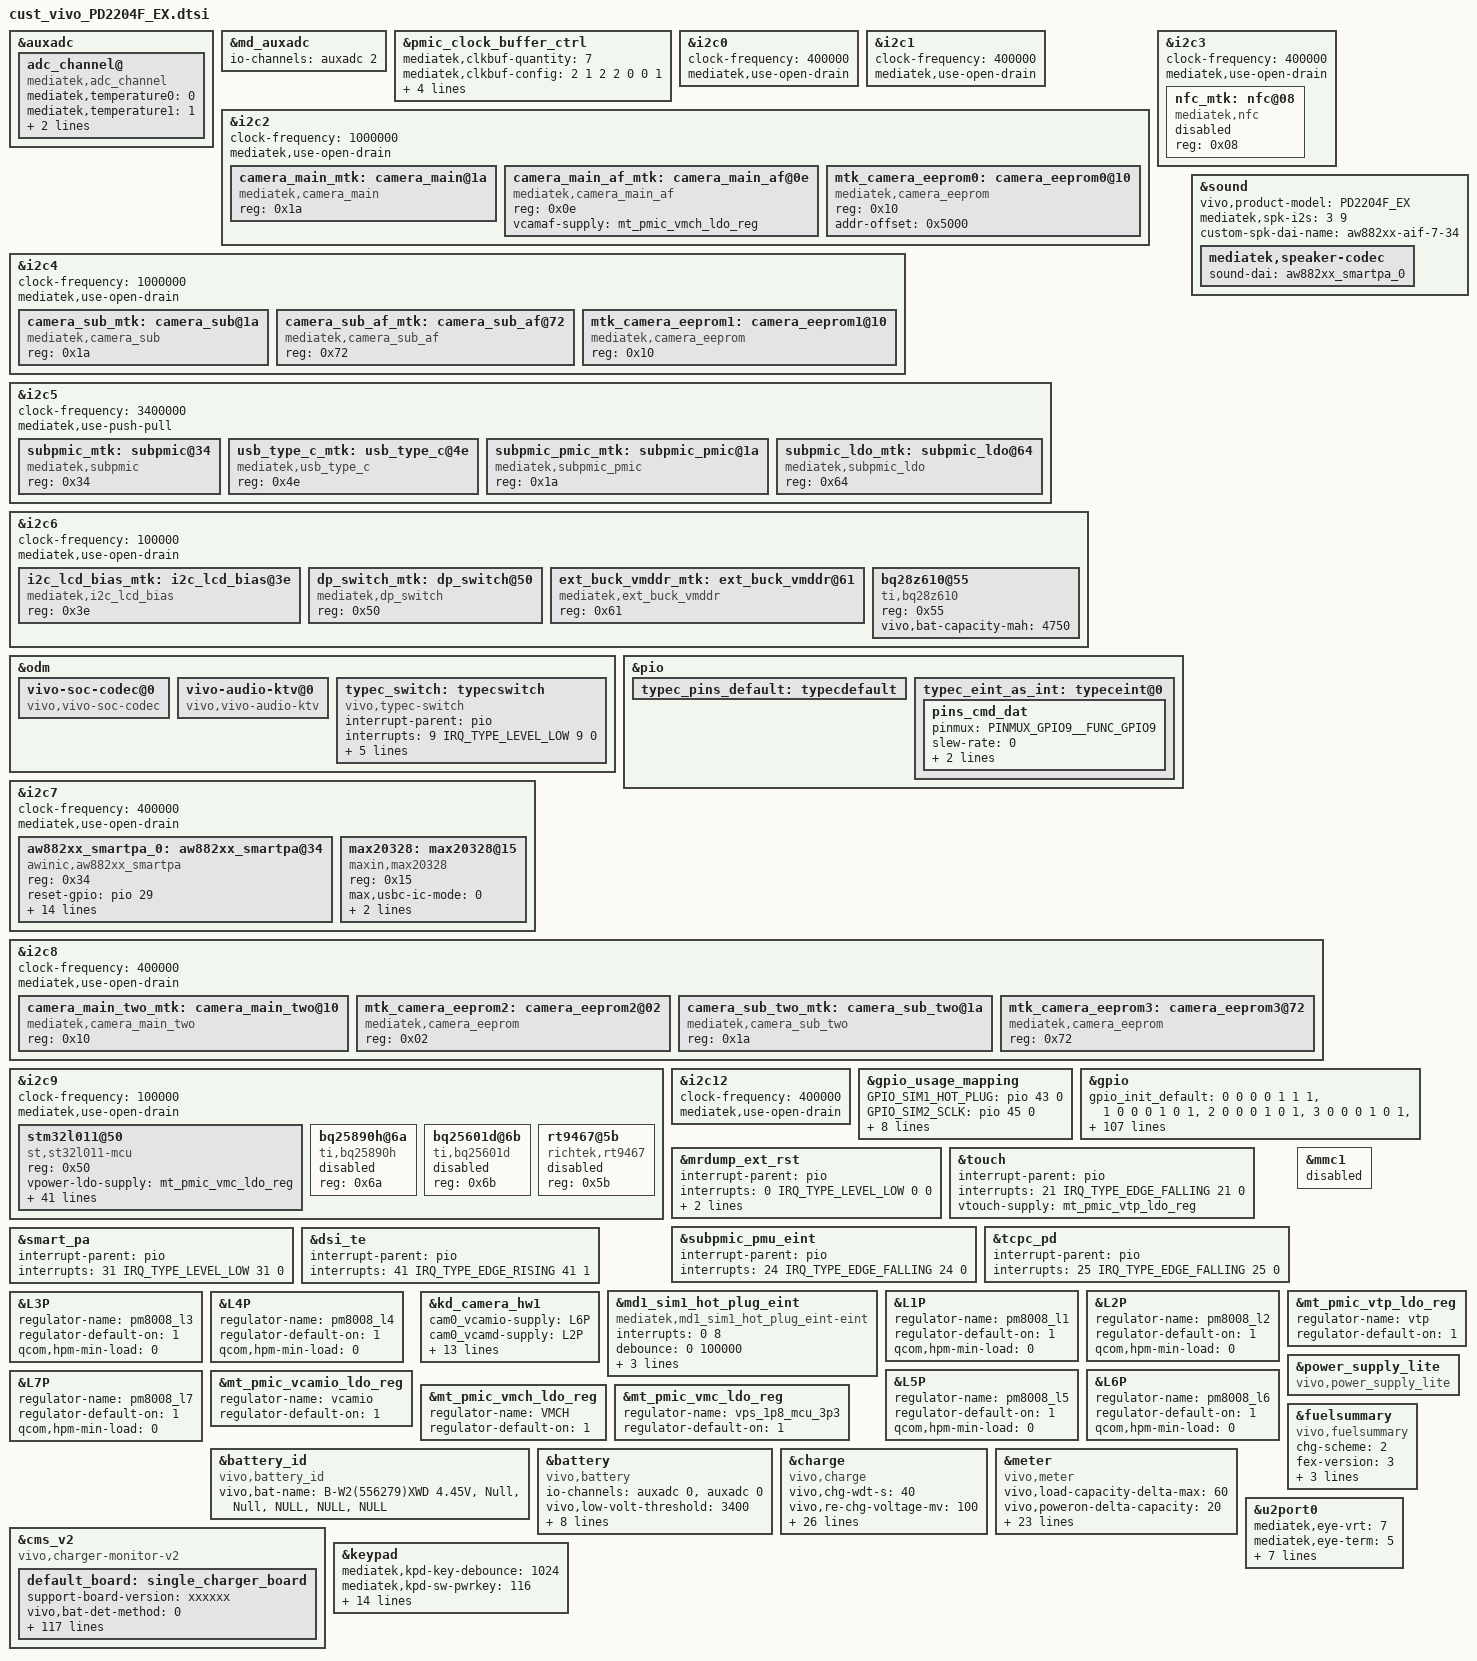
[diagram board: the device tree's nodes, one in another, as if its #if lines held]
/*
 * Generated by MTK SP DrvGen Version: 3.5.160809 for MT6893.
 * 2022-04-22 09:46:38
 * Do Not Modify The File.
 * Copyright Mediatek Inc. (c) 2016.
*/

/*************************
 * ADC DTSI File
*************************/

&auxadc {
	adc_channel@ {
		compatible = "mediatek,adc_channel";
		mediatek,temperature0 = <0>;
		mediatek,temperature1 = <1>;
		mediatek,adc_fdd_rf_params_dynamic_custom_ch = <2>;
		status = "okay";
	};
};
&md_auxadc {
	io-channels = <&auxadc 2>;
};


/*************************
 * CLK_BUF DTSI File
*************************/

&pmic_clock_buffer_ctrl {
	mediatek,clkbuf-quantity = <7>;
	mediatek,clkbuf-config = <2 1 2 2 0 0 1>;
	mediatek,clkbuf-output-impedance = <3 4 3 4 0 0 3>;
	mediatek,clkbuf-controls-for-desense = <0 4 0 4 0 0 0>;
	status = "okay";
};


/*************************
 * I2C DTSI File
*************************/

&i2c0 {
	#address-cells = <1>;
	#size-cells = <0>;
	clock-frequency = <400000>;
	mediatek,use-open-drain;
};

&i2c1 {
	#address-cells = <1>;
	#size-cells = <0>;
	clock-frequency = <400000>;
	mediatek,use-open-drain;
};

&i2c2 {
	#address-cells = <1>;
	#size-cells = <0>;
	clock-frequency = <1000000>;
	mediatek,use-open-drain;
	camera_main_mtk:camera_main@1a {
		compatible = "mediatek,camera_main";
		reg = <0x1a>;
		status = "okay";
	};

	camera_main_af_mtk:camera_main_af@0e {
		compatible = "mediatek,camera_main_af";
		reg = <0x0e>;
		status = "okay";
	};
	mtk_camera_eeprom0:camera_eeprom0@10 {
		compatible = "mediatek,camera_eeprom";
		reg = <0x10>;
		addr-offset = <0x5000>;
		status = "okay";
	};

};

&i2c3 {
	#address-cells = <1>;
	#size-cells = <0>;
	clock-frequency = <400000>;
	mediatek,use-open-drain;
	nfc_mtk:nfc@08 {
		compatible = "mediatek,nfc";
		reg = <0x08>;
		status = "disabled";
	};

};

&i2c4 {
	#address-cells = <1>;
	#size-cells = <0>;
	clock-frequency = <1000000>;
	mediatek,use-open-drain;
	camera_sub_mtk:camera_sub@1a {
		compatible = "mediatek,camera_sub";
		reg = <0x1a>;
		status = "okay";
	};
	camera_sub_af_mtk:camera_sub_af@72 {
		compatible = "mediatek,camera_sub_af";
		reg = <0x72>;
		status = "okay";
	};
	mtk_camera_eeprom1:camera_eeprom1@10 {
		compatible = "mediatek,camera_eeprom";
		reg = <0x10>;
		status = "okay";
	};

};

&i2c5 {
	#address-cells = <1>;
	#size-cells = <0>;
	clock-frequency = <3400000>;
	mediatek,use-push-pull;
	subpmic_mtk:subpmic@34 {
		compatible = "mediatek,subpmic";
		reg = <0x34>;
		status = "okay";
	};

	usb_type_c_mtk:usb_type_c@4e {
		compatible = "mediatek,usb_type_c";
		reg = <0x4e>;
		status = "okay";
	};

	subpmic_pmic_mtk:subpmic_pmic@1a {
		compatible = "mediatek,subpmic_pmic";
		reg = <0x1a>;
		status = "okay";
	};

	subpmic_ldo_mtk:subpmic_ldo@64 {
		compatible = "mediatek,subpmic_ldo";
		reg = <0x64>;
		status = "okay";
	};

};

&i2c6 {
	#address-cells = <1>;
	#size-cells = <0>;
	clock-frequency = <400000>;
	mediatek,use-open-drain;
	i2c_lcd_bias_mtk:i2c_lcd_bias@3e {
		compatible = "mediatek,i2c_lcd_bias";
		reg = <0x3e>;
		status = "okay";
	};

	dp_switch_mtk:dp_switch@50 {
		compatible = "mediatek,dp_switch";
		reg = <0x50>;
		status = "okay";
	};

	ext_buck_vmddr_mtk:ext_buck_vmddr@61 {
		compatible = "mediatek,ext_buck_vmddr";
		reg = <0x61>;
		status = "okay";
	};

};

/* vivo audio dxl add start */
&odm {
	vivo-soc-codec@0 {
		compatible = "vivo,vivo-soc-codec";
		status = "okay";
	};
	vivo-audio-ktv@0 {
		compatible = "vivo,vivo-audio-ktv";
		status = "okay";
	};

	typec_switch:typecswitch {
			compatible = "vivo,typec-switch";
			interrupt-parent = <&pio>;
			interrupts = <9 IRQ_TYPE_LEVEL_LOW 9 0>;
			deb-gpios = <&pio 9 0>;
			debounce = <256000>;
			need_config_Max14743 = <1>;
			pinctrl-names = "default", "typec_eint_as_int";
			pinctrl-0 = <&typec_pins_default>;
			pinctrl-1 = <&typec_eint_as_int>;
			status = "okay";
	};
};

&pio {
	typec_pins_default: typecdefault {
	};
	typec_eint_as_int: typeceint@0 {
			pins_cmd_dat {
					pinmux = <PINMUX_GPIO9__FUNC_GPIO9>;
					slew-rate = <0>;
					/*audio_v: archer modfiy bacause cancel hardware comparator,so not the interrupt.*/
					/*bias-disable;*/
					bias-pull-up;
					input-enable;
			};
	};
};

/* vivo audio dxl add end */

&i2c7 {
	#address-cells = <1>;
	#size-cells = <0>;
	clock-frequency = <400000>;
	mediatek,use-open-drain;
	status = "okay";
	aw882xx_smartpa_0:aw882xx_smartpa@34 {
		compatible = "awinic,aw882xx_smartpa";
		reg = <0x34>;
		#sound-dai-cells = <0>;
		reset-gpio = <&pio 29 0>;
		irq-gpio = <&pio 31 0>;
		sound-channel = <0>;
		//dc-flag = <0>;
		//sync-flag = <0>;
		aw-re-min = <6000>;
		aw-re-max = <10000>;
		aw-cali-mode = "aw_attr";
		aw-cali-check = <1>;

		vivo,Type = "speaker";
		vivo,Impedance-Min-mo = <6000>;
		vivo,Impedance-Max-mo = <10000>;
		vivo,Frequency-Min-hz = <500>;
		vivo,Frequency-Max-hz = <1000>;
		vivo,Qt-Min-1000 = <1000>;
		vivo,VendorID = <63>;       /* AW88263 */
		vivo,aw882xx-acf = "aw882xx_acf_PD2204F_EX.bin";

		status = "okay";
	};
	max20328:max20328@15 {
		status = "okay";
		#sound-dai-cells = <0>;
		compatible = "maxin,max20328";
		reg = <0x15>;
		max,usbc-ic-mode = <0>; /* max20328: 0; fsa4480: 1 */
		jack-type = <1>;   /*0:3.5mm, 1:Type-c*/
		switch-type = <0>; /*0:max20328, 1:FS4480*/
	};
	/* vivo audio dxl add end */
};

&sound {
	vivo,product-model = "PD2204F_EX";
	mediatek,spk-i2s = <3 9>;
	custom-spk-dai-name = "aw882xx-aif-7-34";
	mediatek,speaker-codec {
		sound-dai = <&aw882xx_smartpa_0>;
	};
};

&i2c8 {
	#address-cells = <1>;
	#size-cells = <0>;
	clock-frequency = <400000>;
	mediatek,use-open-drain;
	camera_main_two_mtk:camera_main_two@10 {
		compatible = "mediatek,camera_main_two";
		reg = <0x10>;
		status = "okay";
	};

	mtk_camera_eeprom2:camera_eeprom2@02 {
		compatible = "mediatek,camera_eeprom";
		reg = <0x02>;
		status = "okay";
	};

	camera_sub_two_mtk:camera_sub_two@1a {
		compatible = "mediatek,camera_sub_two";
		reg = <0x1a>;
		status = "okay";
	};
	mtk_camera_eeprom3:camera_eeprom3@72 {
		compatible = "mediatek,camera_eeprom";
		reg = <0x72>;
		status = "okay";
	};
};

&i2c9 {
	#address-cells = <1>;
	#size-cells = <0>;
	clock-frequency = <400000>;
	mediatek,use-open-drain;
	/*
	camera_main_three_mtk:camera_main_three@10 {
		compatible = "mediatek,camera_main_three";
		reg = <0x10>;
		status = "okay";
	};

	camera_main_three_eeprom_mtk:camera_main_three_eeprom@51 {
		compatible = "mediatek,camera_main_three_eeprom";
		reg = <0x51>;
		status = "okay";
	};

	camera_main_three_af_mtk:camera_main_three_af@0c {
		compatible = "mediatek,camera_main_three_af";
		reg = <0x0c>;
		status = "okay";
	};
	*/
};
&i2c12 {
	#address-cells = <1>;
	#size-cells = <0>;
	clock-frequency = <400000>;
	mediatek,use-open-drain;
	#include "pm8008.dtsi"
};


/*************************
 * GPIO DTSI File
*************************/

&gpio_usage_mapping {
	GPIO_SIM1_HOT_PLUG = <&pio 43 0>;
	GPIO_SIM2_SCLK = <&pio 45 0>;
	GPIO_SIM2_SRST = <&pio 46 0>;
	GPIO_SIM2_SIO = <&pio 47 0>;
	GPIO_SIM1_SIO = <&pio 48 0>;
	GPIO_SIM1_SRST = <&pio 49 0>;
	GPIO_SIM1_SCLK = <&pio 50 0>;
	GPIO_FDD_BAND_SUPPORT_DETECT_1ST_PIN = <&pio 70 0>;
	GPIO_FDD_BAND_SUPPORT_DETECT_2ND_PIN = <&pio 185 0>;
};

&gpio{
	gpio_init_default = <0 0 0 0 1 1 1>,
		<1 0 0 0 1 0 1>,
		<2 0 0 0 1 0 1>,
		<3 0 0 0 1 0 1>,
		<4 0 0 0 1 1 1>,
		<5 0 1 0 1 0 1>,
		<6 0 1 0 1 0 1>,
		<7 0 1 0 1 0 1>,
		<8 0 1 0 1 0 1>,
		<9 0 0 0 1 1 1>,
		<10 0 1 0 0 0 0>,//cam3_rst
		<11 0 1 0 0 0 0>,//cam2_rst
		<12 0 0 0 1 1 0>,
		<13 0 1 1 0 0 0>,
		<14 0 1 0 1 0 0>,
		<15 0 0 0 1 0 0>,
		<16 0 0 0 1 0 0>,
		<17 1 0 0 1 0 1>,
		<18 2 0 0 1 0 1>,
		<19 0 1 0 0 0 0>,
		<20 0 0 0 0 1 0>,//pm8008_int
		<21 0 0 0 0 1 1>,
		<22 0 0 0 1 0 1>,
		<23 0 0 0 1 1 1>,
		<24 0 0 0 1 1 1>,
		<25 0 0 0 1 1 1>,
		<26 0 1 0 1 0 1>,
		<27 0 1 1 1 0 1>,
		<28 0 1 0 1 0 1>,
		<29 0 1 0 1 0 1>,
		<30 0 1 0 1 0 1>,
		<31 0 0 0 1 1 1>,
		<32 0 0 0 0 0 1>,
		<33 0 0 0 0 0 1>,
		<34 1 0 0 1 0 1>,
		<35 0 0 0 0 0 1>,
		<36 0 1 0 1 0 0>,
		<37 0 1 0 1 0 0>,
		<38 0 1 0 1 0 0>,
		<39 0 1 0 1 0 0>,
		<40 1 0 0 0 0 0>,
		<41 1 0 0 1 0 0>,
		<42 0 1 0 0 0 0>,
		<43 1 0 0 0 0 1>,
		<44 0 0 0 0 0 0>,
		<45 1 0 0 0 0 1>,
		<46 1 0 0 0 0 1>,
		<47 1 0 0 1 1 1>,
		<48 1 0 0 1 1 1>,
		<49 1 0 0 0 0 1>,
		<50 1 0 0 0 0 1>,
		<51 1 0 0 0 0 1>,
		<52 0 0 0 1 1 1>,
		<53 0 0 0 1 1 1>,
		<54 1 0 0 1 1 1>,
		<55 0 1 0 0 0 1>,
		<56 1 0 0 1 1 1>,
		<57 1 0 0 0 0 0>,
		<58 1 0 0 1 0 0>,
		<59 1 0 0 0 0 0>,
		<60 1 0 0 1 0 0>,
		<61 1 0 0 1 0 0>,
		<62 1 0 0 1 0 1>,
		<63 1 0 0 0 0 1>,
		<64 1 0 0 0 0 1>,
		<65 0 0 0 1 0 0>,
		<66 1 0 0 0 0 1>,
		<67 1 0 0 1 0 0>,
		<68 0 1 1 1 0 0>,
		<69 1 0 0 1 0 0>,
		<70 0 0 0 0 1 1>,
		<71 1 0 0 1 0 0>,
		<72 0 1 1 1 1 0>,
		<73 0 0 0 1 1 0>,
		<74 1 0 0 1 0 0>,
		<75 0 0 0 0 0 1>,
		<76 0 0 0 0 0 1>,
		<77 0 0 0 0 0 1>,
		<78 0 0 0 0 0 1>,
		<79 0 0 0 0 0 1>,
		<80 1 0 0 1 0 0>,
		<81 1 0 0 1 0 0>,
		<82 1 0 0 1 0 0>,
		<83 1 0 0 1 0 0>,
		<84 1 0 0 1 0 0>,
		<85 1 0 0 0 0 0>,
		<86 1 0 0 1 0 0>,
		<87 1 0 0 0 0 0>,
		<88 1 0 0 1 0 0>,
		<89 1 0 0 0 0 1>,
		<90 1 0 0 0 0 1>,
		<92 1 0 0 1 1 0>,
		<93 1 0 0 0 0 0>,
		<94 1 0 0 1 1 0>,
		<95 1 0 0 0 0 0>,
		<96 7 0 0 1 0 0>,
		<97 7 0 0 1 0 0>,
		<98 7 0 0 1 0 0>,
		<99 7 0 0 0 0 0>,
		<100 7 0 0 1 0 0>,
		<101 7 0 0 1 0 0>,
		<102 7 0 0 1 0 0>,
		<103 7 0 0 0 0 0>,
		<104 7 0 0 1 0 0>,
		<105 7 0 0 1 0 0>,
		<106 7 0 0 1 0 0>,
		<107 7 0 0 1 0 1>,
		<108 7 0 0 1 0 0>,
		<109 7 0 0 1 0 0>,
		<110 0 1 0 1 0 0>,
		<111 0 1 0 1 0 0>,
		<112 0 1 0 1 0 0>,
		<113 0 1 0 1 0 0>,
		<114 2 0 0 1 0 0>,
		<115 2 1 0 0 0 0>,
		<116 2 1 0 0 0 0>,
		<117 2 1 0 0 0 0>,
		<118 2 0 0 1 1 1>,
		<119 2 0 0 1 1 1>,
		<120 1 0 0 1 1 1>,
		<121 1 0 0 1 1 1>,
		<122 1 0 0 0 0 1>,//i2c-8  scl  cam2_cam3
		<123 1 0 0 0 0 1>,//i2c-8  sda  cam2_cam3
		<124 1 0 0 1 1 1>,
		<125 1 0 0 1 1 1>,
		<126 4 0 0 1 0 0>,
		<127 4 0 0 1 0 0>,
		<128 5 0 0 0 0 1>,//pm8008_scl
		<129 5 0 0 0 0 1>,//pm8008_sda
		<130 1 0 0 1 0 0>,
		<131 0 1 0 0 0 0>,//cam1_rst
		<132 0 1 0 0 0 0>,//cam0_rst
		<133 0 1 1 1 1 1>,//pm8008_rst
		<134 0 1 1 1 1 1>,//pm8008_en
		<135 0 1 0 0 0 0>,//cam2_dvdd
		<136 0 1 0 1 0 0>,//usb_sw_sel
		<137 1 1 0 0 0 0>,//cam1_mclk
		<138 0 0 0 0 0 0>,
		<139 1 0 0 0 0 1>,//i2c-4  scl  cam1
		<140 1 0 0 0 0 1>,//i2c-4  sda  cam1
		<141 1 0 0 0 0 1>,//i2c-2  scl  cam0
		<142 1 0 0 0 0 1>,//i2c-2  sda  cam0
		<143 0 1 0 1 0 0>,
		<144 0 1 0 1 0 0>,
		<145 0 1 0 1 0 0>,
		<146 0 1 0 1 0 0>,
		<147 0 1 0 1 0 0>,
		<148 0 1 0 1 0 0>,
		<149 1 1 0 0 0 0>,//cam0_mclk
		<150 1 1 0 0 0 0>,//cam3_mclk
		<151 1 1 0 0 0 0>,//cam2_mclk
		<152 0 0 0 1 0 0>,
		<153 1 0 0 0 0 0>,
		<154 1 0 0 1 1 0>,
		<155 0 0 0 0 0 0>,
		<156 1 0 0 0 0 0>,
		<157 1 0 0 0 0 0>,
		<158 1 0 0 0 0 0>,
		<159 1 0 0 0 0 0>,
		<160 1 0 0 1 1 1>,
		<161 1 0 0 1 1 1>,
		<162 0 0 0 1 0 1>,
		<163 0 0 0 1 0 1>,
		<164 0 0 0 1 0 1>,
		<165 1 0 0 1 0 1>,
		<166 1 0 0 1 0 1>,
		<167 0 0 0 1 0 1>,
		<168 6 0 0 1 1 1>,
		<169 6 0 0 1 1 1>,
		<170 6 0 0 1 1 1>,
		<171 6 0 0 1 1 1>,
		<172 0 0 0 1 0 0>,
		<173 0 0 0 1 0 0>,
		<174 0 0 0 1 0 0>,
		<175 0 0 0 1 0 0>,
		<176 0 0 0 1 0 0>,
		<177 0 0 0 1 0 0>,
		<178 0 0 0 1 0 0>,
		<179 0 0 0 1 0 0>,
		<180 0 0 0 1 0 0>,
		<181 0 0 0 1 0 0>,
		<182 0 0 0 1 0 0>,
		<183 0 1 0 1 1 0>,
		<184 0 0 0 0 0 1>,
		<185 0 0 0 0 1 1>,
		<190 0 1 1 0 0 0>,
		<194 0 1 0 0 0 0>,
		<195 1 0 0 0 0 0>,
		<196 1 0 0 0 0 1>,
		<197 1 0 0 0 0 1>,
		<198 1 0 0 0 0 1>,
		<199 1 0 0 1 0 1>,
		<200 1 0 1 1 1 1>,
		<201 1 0 1 1 1 1>,
		<202 1 0 0 1 1 1>,
		<203 1 0 0 1 1 1>,
		<204 1 0 0 0 1 1>,
		<205 1 0 0 0 1 1>,
		<206 1 0 0 0 0 0>,
		<207 1 0 0 0 0 0>,
		<208 1 0 0 0 0 0>,
		<209 1 0 0 1 0 0>,
		<210 1 0 0 0 0 0>,
		<211 1 0 0 0 0 0>,
		<212 1 0 0 0 0 0>,
		<213 1 0 0 1 0 0>,
		<214 1 0 0 0 0 1>,
		<215 1 0 0 0 0 1>,
		<216 1 0 0 0 0 1>,
		<217 1 0 0 0 0 1>,
		<218 1 0 0 1 0 1>,
		<219 1 0 0 1 0 1>,
		<220 0 0 0 1 0 0>,
		<221 0 0 0 1 0 0>,
		<222 0 0 0 1 0 0>,
		<223 0 0 0 1 0 0>,
		<224 0 0 0 1 0 0>,
		<225 0 0 0 1 0 0>,
		<226 0 0 0 1 0 0>;
};


/*************************
 * EINT DTSI File
*************************/

#include <dt-bindings/interrupt-controller/irq.h>
#include <dt-bindings/interrupt-controller/arm-gic.h>

&mrdump_ext_rst {
	interrupt-parent = <&pio>;
	interrupts = <0 IRQ_TYPE_LEVEL_LOW 0 0>;
	deb-gpios = <&pio 0 0>;
	debounce = <512000>;
	status = "okay";
};

&touch {
	interrupt-parent = <&pio>;
	interrupts = <21 IRQ_TYPE_EDGE_FALLING 21 0>;
	status = "okay";
};

&subpmic_pmu_eint {
	interrupt-parent = <&pio>;
	interrupts = <24 IRQ_TYPE_EDGE_FALLING 24 0>;
	status = "okay";
};

&tcpc_pd {
	interrupt-parent = <&pio>;
	interrupts = <25 IRQ_TYPE_EDGE_FALLING 25 0>;
	status = "okay";
};

&smart_pa {
	interrupt-parent = <&pio>;
	interrupts = <31 IRQ_TYPE_LEVEL_LOW 31 0>;
	status = "okay";
};

&dsi_te {
	interrupt-parent = <&pio>;
	interrupts = <41 IRQ_TYPE_EDGE_RISING 41 1>;
	status = "okay";
};



/*************************
 * MD1_EINT DTSI File
*************************/

&md1_sim1_hot_plug_eint {
	compatible = "mediatek,md1_sim1_hot_plug_eint-eint";
	interrupts = <0 8>;
	debounce = <0 100000>;
	dedicated = <0 0>;
	src_pin = <0 1>;
	sockettype = <0 0>;
	status = "okay";
};



/*************************
 * PMIC DTSI File
*************************/
/* hope add pm8008 pmic start*/
&L1P {
	regulator-name = "pm8008_l1";
	regulator-default-on = <1>; /* 0:skip, 1: off, 2:on */
	qcom,hpm-min-load = <0>;
	status = "okay";
};
&L2P {
	regulator-name = "pm8008_l2";
	regulator-default-on = <1>; /* 0:skip, 1: off, 2:on */
	qcom,hpm-min-load = <0>;
	status = "okay";
};
&L3P {
	regulator-name = "pm8008_l3";
	regulator-default-on = <1>; /* 0:skip, 1: off, 2:on */
	qcom,hpm-min-load = <0>;
	status = "okay";
};
&L4P {
	regulator-name = "pm8008_l4";
	regulator-default-on = <1>; /* 0:skip, 1: off, 2:on */
	qcom,hpm-min-load = <0>;
	status = "okay";
};
&L5P {
	regulator-name = "pm8008_l5";
	regulator-default-on = <1>; /* 0:skip, 1: off, 2:on */
	qcom,hpm-min-load = <0>;
	status = "okay";
};
&L6P {
	regulator-name = "pm8008_l6";
	regulator-default-on = <1>; /* 0:skip, 1: off, 2:on */
	qcom,hpm-min-load = <0>;
	status = "okay";
};
&L7P {
	regulator-name = "pm8008_l7";
	regulator-default-on = <1>; /* 0:skip, 1: off, 2:on */
	qcom,hpm-min-load = <0>;
	status = "okay";
};
/* hope add pm8008 pmic end*/

&mmc1 {
    status = "disabled";//disable vmc_ldo
};

&mt_pmic_vcamio_ldo_reg {
	regulator-name = "vcamio";
	regulator-default-on = <1>; /* 0:skip, 1: off, 2:on */
	status = "okay";
};
&mt_pmic_vtp_ldo_reg {
	regulator-name = "vtp";
	regulator-default-on = <1>; /* 0:skip, 1: off, 2:on */
	status = "okay";
};

&kd_camera_hw1 {
	cam0_vcamio-supply = <&L6P>;
	cam0_vcamd-supply = <&L2P>;
	cam0_vcama-supply = <&L3P>;
	cam0_vcamoisa-supply = <&L7P>;

	cam1_vcamio-supply = <&L6P>;
	cam1_vcamd-supply = <&L1P>;
	cam1_vcama-supply = <&L4P>;

	cam2_vcamio-supply = <&L6P>;

	cam2_vcama-supply = <&L5P>;
	cam3_vcamio-supply = <&L6P>;
	cam3_vcama-supply = <&L5P>;
	cam0_enable_sensor = "s5kgw1sd03pd2204f_mipi_raw";
	cam1_enable_sensor = "s5kgd2smpd2204f_mipi_raw";
	cam2_enable_sensor = "ov8856pd2204f_mipi_raw";
	cam3_enable_sensor = "ov02b10pd2204f_mipi_raw";
	status = "okay";
};
&camera_main_af_mtk {
	vcamaf-supply = <&mt_pmic_vmch_ldo_reg>;
};

&touch {
	vtouch-supply = <&mt_pmic_vtp_ldo_reg>;
	status = "okay";
};
&mt_pmic_vmch_ldo_reg {
	regulator-name = "VMCH";
	regulator-default-on = <1>; /* 0:skip, 1: off, 2:on */
	status = "okay";
};

/*************************
 * POWER DTSI File
*************************/
&mt_pmic_vmc_ldo_reg {
	regulator-name = "vps_1p8_mcu_3p3";
	regulator-default-on = <1>; /* 0:skip, 1: off, 2:on */
	status = "okay";
};


/* fuxi add for battery&charge start */
#ifdef CONFIG_VIVO_CHARGING_NEW_ARCH
&battery_id {
	status = "okay";
	compatible = "vivo,battery_id";

	//vivo,bat-adc-ctrl-gpio = <&pio 28 0>;

	//io-channels = <&auxadc 5>;
	//io-channel-names = "battery_id_adc";

	vivo,bat-name = "B-W2(556279)XWD 4.45V","Null","Null","NULL","NULL","NULL";
};

&battery {
	status = "okay";
	compatible = "vivo,battery";

	io-channels = <&auxadc 0>,
		<&auxadc 0>;
	io-channel-names = "primary_board_therm",
		"parallel_board_therm";

	vivo,low-volt-threshold = <3400>;
	vivo,soft-rise-percent = <98>;
	vivo,soft-rise-cumulative = <2>;
	vivo,soft-rise-keep-cumulative = <8>;
	vivo,percnet-sync-delta = <1>;
	vivo,percnet-sync-cumulative = <9>;
	vivo,full-sync-cumulative = <1>;
	vivo,soft-term-percent = <99>;
	vivo,soft-term-cumulative = <15>;
};

&charge {
	status = "okay";
	compatible = "vivo,charge";

	vivo,chg-wdt-s = <40>;
	vivo,re-chg-voltage-mv = <100>;
	vivo,prechg-voltage-mv = <3000>;
	vivo,iprechg-current-ma = <300>;
	vivo,iterm-current-ma = <300>;
	vivo,vreg-voltage-mv = <4460>;
	vivo,vindpm-voltage-mv = <4600>;
	vivo,sys-voltage-min-mv= <3500>;
	vivo,boostv-voltage-mv = <5150>;
	vivo,boostv-ilimit-ma = <1500>;
	vivo,ovp-voltage-mv = <15000>;

	/*
	 * 0  auto detect charging
	 * 1  vivo-normal chargine
	 * 2  vivo-single engine charging
	 * 3  vivo-dual engine charging
	 * 4  vivo-flash charging
	 */
	vivo,charge-scheme = <0>;
	vivo,direct-charger-enable;

	/*
	 * SUPPORTED_ADAPTER_DEFAULT = 0,
	 * SUPPORTED_ADAPTER_VIVO_LV_DCHG_5V_4500MA = 1,
	 * SUPPORTED_ADAPTER_VIVO_HV_DCHG_10V_2250MA = 2,
	 * SUPPORTED_ADAPTER_QC20__9V_2000MA = 3,
	 * SUPPORTED_ADAPTER_VIVO_HV_DCHG_10V_4000MA = 4,
	 * SUPPORTED_ADAPTER_MAX,
	 */
	vivo,supported-adapter = <4>;

	//parameter for 9V2A
	vivo,primary-ichg-max-ma = <2600>;
	vivo,parallel-ichg-max-ma = <1680>;

	vivo,flashchg-spec-ma = <2000 3300 12000>;
	vivo,fastchg-spec-ma = <2000 2100 3800>;
	vivo,normalchg-spec-ma = <2000 1500 2300>;

	/* 0---PMIC; 1---CHGIC */
	vivo,vbus-detect-source = <1>;

	//vivo,usboe-gpio = <&pio 13 0>;

	/*ffc*/
	//vivo,ffc-enable;
	vivo,ffc-iterm-ma = <(-750)>;
	vivo,ffc-vreg-mv = <4490>;
	vivo,ffc-temperature-range = <150 450>;
	vivo,ffc-full-vbat-table-size = <3>;
	vivo,ffc-full-vbat-table = <4470 4470 4430>;
	vivo,ffc-full-ibat-table-size = <3>;
	vivo,ffc-full-ibat-table =<150 199 (-903)>,
		<200 349 (-1164)>,
		<350 449 (-1259)>;
};

&meter {
	status = "okay";
	compatible = "vivo,meter";

	vivo,load-capacity-delta-max = <60>;
	vivo,poweron-delta-capacity = <20>;
	vivo,poweron-low-capacity = <3>;
	vivo,volt-car-delta = <8>;
	vivo,car-volt-delta = <6>;
	vivo,meter-res-compesate = <0>;
	vivo,ocv-board-compesate = <0>;
    	vivo,shipmode-cap-limit = <40>;
	vivo,shipmode-vol-limit = <4000>;

	/* 0---AGING_UNSUPPORTED; 1---DRIVER_SUPPORTED; 2---USPACE_SUPPORTED */
	vivo,battery-aging-support = <2>;

	vivo,capacity-mAh = <4750>;
	/*COLD_CHG COLD_DISCHG NORMAL_CHG NORMAL_DISCHG*/
	vivo,car-tune-value = <1000 1000 1000 1000>,
		<1000 1000 1000 1000>,
		<1000 1000 1000 1000>,
		<1000 1000 1000 1000>,
		<1000 1000 1000 1000>,
		<1000 1000 1000 1000>;
	vivo,bats-qmax = <4100 4200 4320 4480 4480>,
		<3492 3675 3933 4005 4097>,
		<3492 3675 3933 4005 4097>,
		<3492 3675 3933 4005 4097>,
		<3492 3675 3933 4005 4097>,
		<3492 3675 3933 4005 4097>;

	/* car-tune adjust remap */
	vivo,car-tune-adjust-enable;
	vivo,car-tune-adjust-size = <3>;
	vivo,car-tune-adjust-table = <0 10 (330) 7>,
		<11 20 (-30) 9>,
		<21 100 (-30) 11>;

	#include "bat_setting/PD2204F_EX_battery_table.dtsi"
};

&cms_v2 {
	compatible = "vivo,charger-monitor-v2";
	status = "okay";

	default_board: single_charger_board {
		       /*default board: keep in xxxxxx*/
		       support-board-version = "xxxxxx";

		       vivo,bat-det-method = <0>;//r:0, rc:1, eprom:2, ex-fg:3
		       vivo,bat-id-gpio = <&pio 28 0>;

		       /*
			  CHG0__CHARGING_TECHNOLOGY_NONE = 0,
			  CHG1__NORMAL_CHARGING,			//5V/2A normal charging
			  CHG2__QC2_CHARGING,				//9V/2A	QC2.0 charging
			  CHG3__LOW_VOLTAGE_DIRECT_CHARGING,		//5V/4.5A direct charging
			  CHG4__SINGLE_IC_DIV2_CHARGING,		//single IC Div/2 charging
			  CHG5__DUAL_IC_DIV2_CHARGING,			//Dual IC Div/2 charging
			  CHG6__DUAL_IC_DUAL_BATTERY_DIV2_CHARGING,	//Dual IC Div/2 charging
			  CHGX__CHARGING_TECHNOLOGY_MAX,
			*/
		       vivo,charging-technology = <5>;

		       //vivo,no-bat-warning;
		       //vivo,no-chg-timeout;
		       vivo,chg-timeout-mins = <900>;

		       //high temperature charger current control enable
		       vivo,htccc-enable;
		       vivo,htccc-data = <46 55 4000000 100000>;

		       //vivo,fbon-scale-enable;/*disable default*/
		       vivo,fbon-scale-data = <2 100 100>;

		       //vivo,switch-scale-enable;/*disable from rom4.0*/
		       vivo,switch-scale-data = <75 53>;

		       vivo,calling-scale-enable;
		       vivo,calling-scale-data = <100 21>;/*ibat:3900 * 0.54 = 2106,more than 1500,not exit dchg*/
		       vivo,calling-dchg-disable;

		       vivo,weixin-calling-scale-enable;
		       vivo,weixin-calling-scale-data = <100 106>;/*5000mA*/

		       vivo,carlife-scale-enable;
		       vivo,carlife-scale-data = <100 12>;/*500mA*/

		       //vivo,fixed-scale-enable;
		       vivo,fixed-scale-data = <120 3800 0>;/*dchg fixed time adjust the max ibat,disable default*/

		       /*data processing : batt-temp*/
		       vivo,dp-batt-temp-enable;
		       vivo,dp-batt-temp-data = <100>;

		       vivo,vbat-r-comp = <0>;

		       /* charging current for devices in exhibition mode */
		       vivo,exhibition-mode-current-primary = <2048>;
		       vivo,exhibition-mode-current-parallel = <0>;

		       /*default tc parameter*/
		       //single charger ibat scale base on temperature battery cell info:1C/1.2C 3960mah
		       /* tmin, tmax, data, volt1, data_ex1, volt2, data_ex2. */
		       vivo,normal-tc-row-col = <8 9>;
		       vivo,normal-tc-data = <541 8888 0 0 0 0 0 0 0>,
			       <450 540 60 0 0 0 0 0 0>,
			       <200 449 253 4200000 211 4250000 168 0 0>,
			       <150 199 168 4250000 126 0 0 0 0>,
			       <100 149 150 4250000 120 0 0 0 0>,
			       <50 99 100 0 0 0 0 0 0>,
			       <0 49 100 0 0 0 0 0 0>,
			       <(-8888) (-1) 0 0 0 0 0 0 0>;

		       /*flash tc parameter*/
		       vivo,flash-normal-tc-row-col = <10 9>;
		       vivo,flash-normal-tc-data = <541 8888 0 0 0 0 0 0 0>,
			       <450 540 60 0 0 0 0 0 0>,
			       <350 449 253 4220000 210 4250000 160 4430000 140>,
			       <200 349 253 4220000 210 4250000 160 4430000 140>,
			       <150 199 168 4250000 126 4350000 120 4430000 80>,
			       <100 149 150 4250000 120 0 0 0 0>,
			       <50 99 100 0 0 0 0 0 0>,
			       <0 49 100 0 0 0 0 0 0>,
			       <(-50) (-1) 0 0 0 0 0 0 0>,
			       <(-8888) (-51) 0 0 0 0 0 0 0>;

		       /*adjust fastchg base on board temperature and fb off*/
		       vivo,intell-charge-enable;
		       vivo,parallel-temp-enable = <0 0>;//<x y> x:fb-on y:fb-off

		       /* Flash charge fb-on intell param */
		       vivo,primary-fbon-tc-row-col = <9 3>;
		       vivo,primary-fbon-tc-data = <481 8888 1600>,
			       <461 480 2100>,
			       <451 460 2600>,
			       <441 450 3800>,
			       <426 440 4900>,
			       <406 425 6000>,
			       <376 405 7500>,
			       <331 375 10000>,
			       <(-8888) 330 12000>;

		       vivo,parallel-fbon-tc-row-col = <2 3>;
		       vivo,parallel-fbon-tc-data = <481 8888 1600>,
			       <(-8888) 480 12000>;

		       /* Flash charge fb-off intell param */
		       vivo,primary-fboff-tc-row-col = <9 3>;
		       vivo,primary-fboff-tc-data = <461 8888 1600>,
			       <441 460 2500>,
			       <426 440 3200>,
			       <411 425 4100>,
			       <396 410 5400>,
			       <371 395 5900>,
			       <361 370 7700>,
			       <331 360 10000>,
			       <(-8888) 330 12000>;

		       vivo,parallel-fboff-tc-row-col = <2 3>;
		       vivo,parallel-fboff-tc-data = <461 8888 1600>,
			       <(-8888) 460 12000>;


		       /* 9v Fast charge fb-on intell param */
		       vivo,9v-primary-fbon-tc-row-col = <7 3>;
		       vivo,9v-primary-fbon-tc-data = <481 8888 500>,
			       <461 480 700>,
			       <441 460 900>,
			       <421 440 1300>,
			       <401 420 1700>,
			       <381 400 2100>,
			       <(-8888) 380 2500>;
		       vivo,9v-parallel-fbon-tc-row-col = <7 3>;
		       vivo,9v-parallel-fbon-tc-data = <481 8888 500>,
			       <461 480 800>,
			       <441 460 900>,
			       <421 440 1300>,
			       <401 420 1700>,
			       <381 400 2100>,
			       <(-8888) 380 2500>;
		       // second parallel parameter, for rt9467
		       vivo,9v-2nd-parallel-fbon-tc-row-col = <3 3>;
		       vivo,9v-2nd-parallel-fbon-tc-data = <401 8888 512>,
			       <386 400 800>,
			       <(-8888) 385 1000>;


		       /* 9v Fast charge fb-off intell param */
		       vivo,9v-primary-fboff-tc-row-col = <7 3>;
		       vivo,9v-primary-fboff-tc-data = <451 8888 800>,
			       <441 450 1100>,
			       <431 440 1300>,
			       <421 430 1600>,
			       <411 420 1900>,
			       <401 410 2200>,
			       <(-8888) 400 2500>;
		       vivo,9v-parallel-fboff-tc-row-col = <7 3>;
		       vivo,9v-parallel-fboff-tc-data = <451 8888 800>,
			       <441 450 1100>,
			       <431 440 1300>,
			       <421 430 1600>,
			       <411 420 1900>,
			       <401 410 2200>,
			       <(-8888) 400 2500>;
		       // second parallel parameter, for rt9467
		       vivo,9v-2nd-parallel-fboff-tc-row-col = <6 3>;
		       vivo,9v-2nd-parallel-fboff-tc-data = <431 8888 500>,
			       <411 430 700>,
			       <381 410 790>,
			       <371 380 1050>,
			       <351 370 1300>,
			       <(-8888) 350 1500>;


		       /* 5v Normal charge fb-on intell param */
		       vivo,5v-primary-fbon-tc-row-col = <6 3>;
		       vivo,5v-primary-fbon-tc-data = <481 8888 500>,
			       <461 480 700>,
			       <441 460 900>,
			       <421 440 1300>,
			       <401 420 1700>,
			       <(-8888) 400 2000>;

		       vivo,5v-parallel-fbon-tc-row-col = <1 3>;
		       vivo,5v-parallel-fbon-tc-data = <(-8888) 8888 0>;

		       /* 5v Normal charge fb-off intell param */
		       vivo,5v-primary-fboff-tc-row-col = <6 3>;
		       vivo,5v-primary-fboff-tc-data = <451 8888 800>,
			       <441 450 1100>,
			       <431 440 1300>,
			       <421 430 1600>,
			       <411 420 1900>,
			       <(-8888) 410 2000>;

		       vivo,5v-parallel-fboff-tc-row-col = <1 3>;
		       vivo,5v-parallel-fboff-tc-data = <(-8888) 8888 0>;

		       // Direct charging param
		       vivo,direct-charger-enable;//porting_check
		       vivo,ex-bms-psy-name = "bq_bms";

		       // bat_baord, usb_conn, pcb_conn(master_bat_conn), bat_conn
		       vivo,dchg-ntc-protect-enable;
		       vivo,dchg-ntc-protect-data = <750 800 850 850>;

		       vivo,adapter-cooldown-data = <900 850 3400>;
		       /*adapter power derate*/
		       vivo,adapter-power-derate-enable;

		       /* usb connecter protect param
			* USB_PROTECT_NONE = 0,
			* USB_CONN_TEMP_HEAT_PROTECT = BIT(0),
			* USB_ID_PROTECT = BIT(1),
			*/
		       vivo,usb-connecter-protect-enable = <1>;
		       vivo,usb-id-protect-data= <1100 1547 500>;/* 500K, 2M, fcc */
		       vivo,usb-conn-heat-protect-data-row-col = <2 4>;
		       vivo,usb-conn-heat-protect-data= <260 8888 670 620>,
			       <(-8888) 259 570 520>;

		       /*
			* max vbus of adapter:11v, max ibus of adapter:5A
			* min voltage of battery for half chg:3500mV,max voltage of battery for half charge:4100mV,
			* 5V2A charge min current threshold: 1000mA,5V2A charge max current threshold:2100mA,
			* flash charge min current threshold:5000mA,flash charge max current threshold:11000mA
			*/

		       /*default parameter*/
		       vivo,charge-param-judge-threshold = <5 2 3500 4300 1000 2100 5000 11000>;
		       /* factory mode charging test param */
		       vivo,charge-test-param-row-col = <12 3>;
		       vivo,charge-test-param-data = <0 0 5500>, /* cable resistance, min value, max value */
			       <0 0 5500>, /* master ibus, min ibus, max ibus */
			       <0 0 5500>, /* slave ibus, min ibus, max ibus */
			       <1 20 40>, /* batt therm ntc, min value, max value */
			       <1 20 45>, /* board therm ntc, min value, max value */
			       <0 20 50>, /* sub charger ntc, min value, max value */
			       <0 20 45>, /* usb con ntc, min value, max value */
			       <0 20 45>, /* usb con 1 ntc, double usb NTC, min value, max value */
			       <0 20 45>, /* bat btb master ntc, min value, max value */
			       <0 20 50>, /* bat btb sub ntc, min value, max value */
			       <0 20 50>, /* bat board ntc, min value, max value */
			       <0 20 50>; /* wireless charge coil ntc, min value, max value */

		       /*flash parameter*/
		       vivo,flash-charge-param-judge-threshold = <11 6 3500 4100 1000 2200 8000 12000>;
		       /* factory mode charging test param */
		       vivo,flash-charge-test-param-row-col = <12 3>;
		       vivo,flash-charge-test-param-data = <1 0 5500>, /* cable resistance, min value, max value */
			       <1 0 5500>, /* master ibus, min ibus, max ibus */
			       <1 0 5500>, /* slave ibus, min ibus, max ibus */
			       <1 20 40>, /* batt therm ntc, min value, max value */
			       <1 20 45>, /* board therm ntc, min value, max value */
			       <0 20 50>, /* sub charger ntc, min value, max value */
			       <1 20 45>, /* usb con ntc, min value, max value */
			       <0 20 45>, /* usb con 1 ntc, double usb NTC, min value, max value */
			       <1 20 45>, /* bat btb master ntc, min value, max value */
			       <0 20 50>, /* bat btb sub ntc, min value, max value */
			       <0 20 50>, /* bat board ntc, min value, max value */
			       <0 20 50>; /* wireless charge coil ntc, min value, max value */

		       #include "bat_setting/PD2204F_EX_battery_chg_params.dtsi"
	       };
};

&power_supply_lite {
	status = "okay";
	compatible = "vivo,power_supply_lite";
};

&fuelsummary {
	status = "okay";
	compatible = "vivo,fuelsummary";

	/************************************************************
	 *
	 *  0   vivo-fastchg
	 *  1   qcom-dualchg
	 *  2   mtk-dualchg
	 *  3   qcom-normchg
	 *  4   mtk-normchg
	 *
	 ***********************************************************/
	chg-scheme = <2>;
	fex-version = <3>;
	fbon-ibat = <(-900)>;
	fboff-ibat = <(-1000)>;

	/* 0---AGING_UNSUPPORTED; 1---DRIVER_SUPPORTED; 2---USPACE_SUPPORTED */
	vivo,battery-aging-support = <2>;
};

&i2c6 {
	status = "okay";
	#address-cells = <1>;
	#size-cells = <0>;
	clock-frequency = <100000>;
	mediatek,use-open-drain;

	bq28z610@55 {
		compatible = "ti,bq28z610";
		reg = <0x55>;
		//vivo,skip-sha;
		vivo,bat-capacity-mah = <4750>;
	};

};


&i2c9 {
	#address-cells = <1>;
	#size-cells = <0>;
	status = "okay";
	clock-frequency = <100000>;

	stm32l011@50 {
		compatible = "st,st32l011-mcu";
		reg = <0x50>;
		status = "okay";

		vpower-ldo-supply = <&mt_pmic_vmc_ldo_reg>;
		//vivo,power-gpio = <&pio 27 0>;//ZC_LDO_EN
		vivo,int-gpio = <&pio 6 0>;//MCU_INT_AP
		vivo,usben-gpio = <&pio 194 0>;//USB_SW_EN
		vivo,usbsel-gpio = <&pio 136 0>;//USB_SW_SEL
		vivo,shift-en-gpio = <&pio 8 0>;//SHIFT_EN
		vivo,sbu-pwr-gpio = <&pio 19 0>;
		//vivo,mcu-version-gpio = <&pio 186 0>;
		//vivo,chgic-version-gpio = <&pio 189 0>;
		//vivo,chgic-version-reverse;
		ti,temp-cold-degc = <2>;
		ti,temp-hot-degc = <43>;
		vivo,total-limit-max-ma = <8000>;
		vivo,bigdata-collect-time-limit = <95>;//seconds
		vivo,direct-charger-enable;//porting_check

		/*FFC charge: */
		vivo,ffc-support;
		vivo,ffc-temperature-range = <150 450>;
		//vivo,ffc-param-tuning-enable = <1963>;
		vivo,ffc-cc-to-cv-ibat-thr-rc = <1 3>;
		/*<Tmin Tmax current>*/
		vivo,ffc-cc-to-cv-ibat-thr-table = <150 450 3800>;
		vivo,ffc-dchg-cv-mv-rc = <3 2>;
		/*btb_cv,fg_cv*/
		vivo,ffc-dchg-cv-mv-table = <4470 4470>,/*default*/
			<4493 4470>,/*single_charging*/
			<4519 4470>;/*dual_charging*/

		vivo,battery-id-ffc-dchg-btb_cv-mv-table = <4493 4493 4493 4493 4493 4493>;
		vivo,battery-id-ffc-dchg-fg_cv-mv-table = <4470 4470 4470 4470 4470 4470>;

		//vivo,cout-int-gpio = <&pio 112 0>;

		vivo,sbu-cable-id-detect-enable;
		vivo,sbu-detect-rely-usb-switch;
		//vivo,sbu-id-detect-from-ex-adc;

		vivo,bat-board-temp-enable = <3>;
		vivo,usb-conn-temp-enable = <1>;
		vivo,bat-conn-temp-enable = <2>;

		vivo,master-bat-conn-temp-enable = <1>;
		vivo,dchg-exit-ntc-threshold = <750 650 700 700 1200>;

		/* BQ25970_SINGLE_DCHG:
		 * DCHG_SINGLE_TYPE_22P5W = 0,
		 * DCHG_SINGLE_TYPE_33W = 1,
		 * DCHG_SINGLE_TYPE_44W = 2,
		 * BQ25970_DUAL_DCHG:DCHG_DUAL_TYPE_44W = 3,
		 */
		vivo,dchg-supported-type = <3>;
		/*adapter power derate*/
		vivo,adapter-power-derate-enable;

		//vivo,single-charger-enable;
		vivo,adapter-sha-encryption;

		io-channels = <&auxadc 5>,
			<&auxadc 4>,
			<&auxadc 3>;

		io-channel-names = "bat_conn_temp",
			"sbu1_cable_id_adc",
			"sbu2_cable_id_adc";

		/*cable r limit table :
		  <rmin,rmax, dchg_ibus_max, cable_id_type, limit_count>
		  cable_id_type: 0:effective cable id, 1:other(default) cable id
		 */
		vivo,cable-r-limit-table-rc = <9 5>;
		vivo,cable-r-limit-table = <(-8888) 220 6000 0 0>,
			<221 278 3000 0 0>,
			<279 343 2250 0 0>,
			<344 454 1800 0 0>,
			<455 8888 0 0 0>,
			<(-8888) 385 3000 1 0>,
			<386 450 2250 1 0>,
			<451 561 1800 1 0>,
			<562 8888 0 1 0>;

		/*load firmware profile*/
		vivo,fw-id-range-pct = <100>;
		#include "bat_setting/mcu-firmware-data-66w-nation-ln8000.dtsi"
	};

	bq25890h@6a {
		status = "disable";
		compatible = "ti,bq25890h";
		reg = <0x6a>;

		//vivo,int-gpio = <&pio 11 0>;
	};

	bq25601d@6b {
		status = "disable";
		compatible = "ti,bq25601d";
		reg = <0x6b>;

		//vivo,int-gpio = <&pio 11 0>;
		//vivo,enable-gpio = <&pio 69 0>;
	};

	rt9467@5b {
		status = "disable";
		compatible = "richtek,rt9467";
		reg = <0x5b>;

		//vivo,int-gpio = <&pio 3 0>;
		//vivo,enable-gpio = <&pio 166 0>;
	};
};
#endif
/* fuxi add for battery&charge end */
/*************************
 * KPD DTSI File
*************************/

&keypad {
	mediatek,kpd-key-debounce = <1024>;
	mediatek,kpd-sw-pwrkey = <116>;
	mediatek,kpd-hw-pwrkey = <8>;
	mediatek,kpd-sw-rstkey  = <114>;
	mediatek,kpd-hw-rstkey = <17>;
	mediatek,kpd-use-extend-type = <0>;
	/*HW Keycode [0~71] -> Linux Keycode*/
	mediatek,kpd-hw-map-num = <72>;
	mediatek,kpd-hw-init-map = <115 0 0 0 0 0 0 0 0 0 0 0 0 0 0 0 0 0 0 0 0 0 0 0 0 0 0 0 0 0 0 0 0 0 0 0 0 0 0 0 0 0 0 0 0 0 0 0 0 0 0 0 0 0 0 0 0 0 0 0 0 0 0 0 0 0 0 0 0 0 0 0 >;
	mediatek,kpd-pwrkey-eint-gpio = <0>;
	mediatek,kpd-pwkey-gpio-din  = <0>;
	mediatek,kpd-hw-dl-key0 = <17>;
	mediatek,kpd-hw-dl-key1 = <0>;
	mediatek,kpd-hw-dl-key2 = <8>;
	mediatek,kpd-hw-recovery-key = <17>;
	mediatek,kpd-hw-factory-key = <0>;
	status = "okay";
};

//vivo panyaqin add for usb eye begin
&u2port0{
    mediatek,eye-vrt = <7>; /* 0~7 */
    mediatek,eye-term = <5>; /* 0~7 */
    mediatek,eye-rev6 = <3>; /* 0~3 */
    mediatek,eye-intr = <0x1e>; /* 0~0xlf */
    mediatek,eye-disc = <7>; /* 0~8 */
    mediatek,host-eye-vrt = <7>; /* 0~7 */
    mediatek,host-eye-term = <4>; /* 0~7 */
    mediatek,host-eye-rev6 = <3>; /* 0~3 */
    mediatek,host-eye-disc = <7>; /* 0~8 */
};
//vivo panyaqin add for usb eye begin

